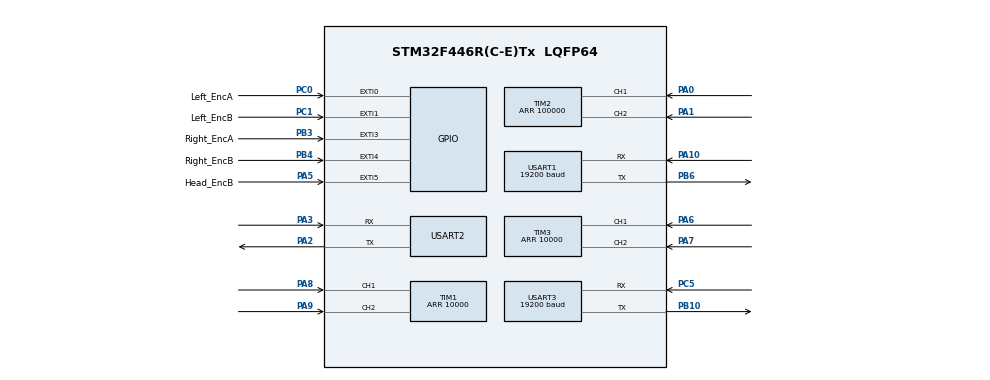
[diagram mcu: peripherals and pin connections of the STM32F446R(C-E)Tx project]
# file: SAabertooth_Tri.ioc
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Mcu.Family=STM32F4
Mcu.Name=STM32F446R(C-E)Tx
Mcu.Package=LQFP64
NVIC.EXTI0_IRQn=true\:0\:0\:false\:false\:true\:true\:true
NVIC.EXTI1_IRQn=true\:0\:0\:false\:false\:true\:true\:true
NVIC.EXTI3_IRQn=true\:0\:0\:false\:false\:true\:true\:true
NVIC.PriorityGroup=NVIC_PRIORITYGROUP_4
PA0-WKUP.Signal=S_TIM2_CH1_ETR
PA1.Signal=S_TIM2_CH2
PA10.Mode=Asynchronous
PA10.Signal=USART1_RX
PA13.Mode=Serial_Wire
PA13.Signal=SYS_JTMS-SWDIO
PA14.Mode=Serial_Wire
PA14.Signal=SYS_JTCK-SWCLK
PA2.Mode=Asynchronous
PA2.Signal=USART2_TX
PA3.Mode=Asynchronous
PA3.Signal=USART2_RX
PA5.GPIO_Label=Head_EncB
PA5.Signal=GPXTI5
PA6.Signal=S_TIM3_CH1
PA7.Signal=S_TIM3_CH2
PA8.Signal=S_TIM1_CH1
PA9.Signal=S_TIM1_CH2
PB10.Mode=Asynchronous
PB10.Signal=USART3_TX
PB3.GPIO_Label=Right_EncA
PB3.GPIO_PuPd=GPIO_PULLUP
PB3.Signal=GPXTI3
PB4.GPIO_Label=Right_EncB
PB4.Signal=GPXTI4
PB6.Mode=Asynchronous
PB6.Signal=USART1_TX
PC0.GPIO_Label=Left_EncA
PC0.Signal=GPXTI0
PC1.GPIO_Label=Left_EncB
PC1.GPIO_PuPd=GPIO_PULLUP
PC1.Signal=GPXTI1
PC5.Mode=Asynchronous
PC5.Signal=USART3_RX
PH0-OSC_IN.Mode=HSE-External-Oscillator
PH0-OSC_IN.Signal=RCC_OSC_IN
PH1-OSC_OUT.Mode=HSE-External-Oscillator
PH1-OSC_OUT.Signal=RCC_OSC_OUT
ProjectManager.HeapSize=0x200
ProjectManager.StackSize=0x400
ProjectManager.TargetToolchain=STM32CubeIDE
RCC.CortexFreq_Value=16000000
RCC.USBFreq_Value=96000000
RCC.VCOOutputFreq_Value=192000000
SH.S_TIM1_CH1.0=TIM1_CH1,Encoder_Interface
SH.S_TIM1_CH2.0=TIM1_CH2,Encoder_Interface
SH.S_TIM2_CH1_ETR.0=TIM2_CH1,Encoder_Interface
SH.S_TIM2_CH2.0=TIM2_CH2,Encoder_Interface
SH.S_TIM3_CH1.0=TIM3_CH1,Encoder_Interface
SH.S_TIM3_CH2.0=TIM3_CH2,Encoder_Interface
TIM1.Period=10000
TIM2.Period=100000
TIM3.Period=10000
USART1.BaudRate=19200
USART1.VirtualMode=VM_ASYNC
USART2.VirtualMode=VM_ASYNC
USART3.BaudRate=19200
USART3.VirtualMode=VM_ASYNC
board=custom

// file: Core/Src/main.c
/* USER CODE BEGIN Header */
/**
  ******************************************************************************
  * @file           : main.c
  * @brief          : Main program body
  ******************************************************************************
  * @attention
  *
  * <h2><center>&copy; Copyright (c) 2021 STMicroelectronics.
  * All rights reserved.</center></h2>
  *
  * This software component is licensed by ST under BSD 3-Clause license,
  * the "License"; You may not use this file except in compliance with the
  * License. You may obtain a copy of the License at:
  *                        opensource.org/licenses/BSD-3-Clause
  *
  ******************************************************************************
  */
/* USER CODE END Header */
#include "main.h"

/* USER CODE BEGIN PTD */
    void Write_Command(uint8_t , uint8_t);
	void motor(uint8_t motor , int8_t power);
	void SetBaudRate(uint16_t BaudRate);

	//Function Decleration For 2nd Sabertooth...

	void Write_CommandA(uint8_t, uint8_t);
	void motorA(uint8_t motor1 , int8_t power1);
	void SetBaudRateA(uint16_t BaudRate);
/* USER CODE END PTD */

TIM_HandleTypeDef htim1;
TIM_HandleTypeDef htim2;
TIM_HandleTypeDef htim3;

UART_HandleTypeDef huart1;
UART_HandleTypeDef huart2;
UART_HandleTypeDef huart3;

void SystemClock_Config(void);
static void MX_GPIO_Init(void);
static void MX_TIM1_Init(void);
static void MX_TIM2_Init(void);
static void MX_TIM3_Init(void);
static void MX_USART1_UART_Init(void);
static void MX_USART2_UART_Init(void);
static void MX_USART3_UART_Init(void);

int main(void)
{
  /* MCU Configuration--------------------------------------------------------*/
//Function Declaration for 1st Motor....

  /* Reset of all peripherals, Initializes the Flash interface and the Systick. */
  HAL_Init();

  /* Configure the system clock */
  SystemClock_Config();

  /* Initialize all configured peripherals */
  MX_GPIO_Init();
  MX_TIM1_Init();
  MX_TIM2_Init();
  MX_TIM3_Init();
  MX_USART1_UART_Init();
  MX_USART2_UART_Init();
  MX_USART3_UART_Init();
  /* USER CODE BEGIN 2 */
  SetBaudRate(19200);
  SetBaudRateA(19200);
  /* USER CODE END 2 */

  /* Infinite loop */
  while (1)
  {
	 motor(1,40);
	 motor(2,40);
	 motorA(2,40);
  }
}

//1st Sabertooth with 2 Motors i.e. Head Motor and Left Motor.....
void SetBaudRate(uint16_t BaudRate)
{
	  uint8_t value;
	  switch(BaudRate)
		{
			case 9600 : value = 2 ;
									break;
			case 19200: default : value = 3;
									break;
		}

		HAL_Delay(500);
		Write_Command(15 , value);
		HAL_Delay(2000);
}

char PacketAddress[2];
char Command[2];
char Value[2];
char AllWrite[2];
uint8_t packetaddress = 128;

void Write_Command(uint8_t command , uint8_t value)
{
	PacketAddress[0] = packetaddress;
	Command[0] = command;
	Value[0] = value;
	HAL_UART_Transmit(&huart1 , (uint8_t*)PacketAddress , 1 , 2000);
	HAL_UART_Transmit(&huart1 , (uint8_t*)Command , 1 ,2000);
	HAL_UART_Transmit(&huart1 , (uint8_t*)Value , 1 , 2000);
	AllWrite[0] = ((packetaddress + command + value) & 127);
	HAL_UART_Transmit(&huart1 , (uint8_t*)AllWrite , 1 , 2000);
}
void motor(uint8_t motor , int8_t power)
{
	Write_Command(((motor == 2?4:0) + (power<0?1:0)) , (power<0?-power:power));
}

//Second Sabertooth with Only 1 Motor....
void SetBaudRateA(uint16_t BaudRateA)
{
	  uint8_t valueA;
	  switch(BaudRateA)
		{
			case 9600 : valueA = 2 ;
									break;
			case 19200: default : valueA = 3;
									break;
		}

		HAL_Delay(500);
		Write_CommandA(15 , valueA);
		HAL_Delay(2000);
}

char PacketAddressA[2];
char CommandA[2];
char ValueA[2];
char AllWriteA[2];
uint8_t packetaddressA = 128;

void Write_CommandA(uint8_t commandA , uint8_t valueA)
{
	PacketAddressA[0] = packetaddressA;
	CommandA[0] = commandA;
	ValueA[0] = valueA;
	HAL_UART_Transmit(&huart3 , (uint8_t*)PacketAddressA , 1 , 2000);
	HAL_UART_Transmit(&huart3 , (uint8_t*)CommandA , 1 ,2000);
	HAL_UART_Transmit(&huart3 , (uint8_t*)ValueA , 1 , 2000);
	AllWriteA[0] = ((packetaddressA + commandA + valueA) & 127);
	HAL_UART_Transmit(&huart3 , (uint8_t*)AllWriteA , 1 , 2000);
}
void motorA(uint8_t motorA , int8_t powerA)
{
	Write_CommandA(((motorA == 2?4:0) + (powerA<0?1:0)) , (powerA<0?-powerA:powerA));
}

 // * @brief System Clock Configuration
  //* @retval None

void SystemClock_Config(void)
{
  RCC_OscInitTypeDef RCC_OscInitStruct = {0};
  RCC_ClkInitTypeDef RCC_ClkInitStruct = {0};

  /** Configure the main internal regulator output voltage
  */
  __HAL_RCC_PWR_CLK_ENABLE();
  __HAL_PWR_VOLTAGESCALING_CONFIG(PWR_REGULATOR_VOLTAGE_SCALE3);
  /** Initializes the RCC Oscillators according to the specified parameters
  * in the RCC_OscInitTypeDef structure.
  */
  RCC_OscInitStruct.OscillatorType = RCC_OSCILLATORTYPE_HSI;
  RCC_OscInitStruct.HSIState = RCC_HSI_ON;
  RCC_OscInitStruct.HSICalibrationValue = RCC_HSICALIBRATION_DEFAULT;
  RCC_OscInitStruct.PLL.PLLState = RCC_PLL_NONE;
  if (HAL_RCC_OscConfig(&RCC_OscInitStruct) != HAL_OK)
  {
    Error_Handler();
  }
  /** Initializes the CPU, AHB and APB buses clocks
  */
  RCC_ClkInitStruct.ClockType = RCC_CLOCKTYPE_HCLK|RCC_CLOCKTYPE_SYSCLK
                              |RCC_CLOCKTYPE_PCLK1|RCC_CLOCKTYPE_PCLK2;
  RCC_ClkInitStruct.SYSCLKSource = RCC_SYSCLKSOURCE_HSI;
  RCC_ClkInitStruct.AHBCLKDivider = RCC_SYSCLK_DIV1;
  RCC_ClkInitStruct.APB1CLKDivider = RCC_HCLK_DIV1;
  RCC_ClkInitStruct.APB2CLKDivider = RCC_HCLK_DIV1;

  if (HAL_RCC_ClockConfig(&RCC_ClkInitStruct, FLASH_LATENCY_0) != HAL_OK)
  {
    Error_Handler();
  }
}

/*
  * @brief TIM1 Initialization Function
  * @param None
  * @retval None
  */
static void MX_TIM1_Init(void)
{

  TIM_Encoder_InitTypeDef sConfig = {0};
  TIM_MasterConfigTypeDef sMasterConfig = {0};

  htim1.Instance = TIM1;
  htim1.Init.Prescaler = 0;
  htim1.Init.CounterMode = TIM_COUNTERMODE_UP;
  htim1.Init.Period = 10000;
  htim1.Init.ClockDivision = TIM_CLOCKDIVISION_DIV1;
  htim1.Init.RepetitionCounter = 0;
  htim1.Init.AutoReloadPreload = TIM_AUTORELOAD_PRELOAD_DISABLE;
  sConfig.EncoderMode = TIM_ENCODERMODE_TI1;
  sConfig.IC1Polarity = TIM_ICPOLARITY_RISING;
  sConfig.IC1Selection = TIM_ICSELECTION_DIRECTTI;
  sConfig.IC1Prescaler = TIM_ICPSC_DIV1;
  sConfig.IC1Filter = 0;
  sConfig.IC2Polarity = TIM_ICPOLARITY_RISING;
  sConfig.IC2Selection = TIM_ICSELECTION_DIRECTTI;
  sConfig.IC2Prescaler = TIM_ICPSC_DIV1;
  sConfig.IC2Filter = 0;
  if (HAL_TIM_Encoder_Init(&htim1, &sConfig) != HAL_OK)
  {
    Error_Handler();
  }
  sMasterConfig.MasterOutputTrigger = TIM_TRGO_RESET;
  sMasterConfig.MasterSlaveMode = TIM_MASTERSLAVEMODE_DISABLE;
  if (HAL_TIMEx_MasterConfigSynchronization(&htim1, &sMasterConfig) != HAL_OK)
  {
    Error_Handler();
  }

}

static void MX_TIM2_Init(void)
{

  TIM_Encoder_InitTypeDef sConfig = {0};
  TIM_MasterConfigTypeDef sMasterConfig = {0};

  htim2.Instance = TIM2;
  htim2.Init.Prescaler = 0;
  htim2.Init.CounterMode = TIM_COUNTERMODE_UP;
  htim2.Init.Period = 100000;
  htim2.Init.ClockDivision = TIM_CLOCKDIVISION_DIV1;
  htim2.Init.AutoReloadPreload = TIM_AUTORELOAD_PRELOAD_DISABLE;
  sConfig.EncoderMode = TIM_ENCODERMODE_TI1;
  sConfig.IC1Polarity = TIM_ICPOLARITY_RISING;
  sConfig.IC1Selection = TIM_ICSELECTION_DIRECTTI;
  sConfig.IC1Prescaler = TIM_ICPSC_DIV1;
  sConfig.IC1Filter = 0;
  sConfig.IC2Polarity = TIM_ICPOLARITY_RISING;
  sConfig.IC2Selection = TIM_ICSELECTION_DIRECTTI;
  sConfig.IC2Prescaler = TIM_ICPSC_DIV1;
  sConfig.IC2Filter = 0;
  if (HAL_TIM_Encoder_Init(&htim2, &sConfig) != HAL_OK)
  {
    Error_Handler();
  }
  sMasterConfig.MasterOutputTrigger = TIM_TRGO_RESET;
  sMasterConfig.MasterSlaveMode = TIM_MASTERSLAVEMODE_DISABLE;
  if (HAL_TIMEx_MasterConfigSynchronization(&htim2, &sMasterConfig) != HAL_OK)
  {
    Error_Handler();
  }

}

static void MX_TIM3_Init(void)
{

  TIM_Encoder_InitTypeDef sConfig = {0};
  TIM_MasterConfigTypeDef sMasterConfig = {0};

  htim3.Instance = TIM3;
  htim3.Init.Prescaler = 0;
  htim3.Init.CounterMode = TIM_COUNTERMODE_UP;
  htim3.Init.Period = 10000;
  htim3.Init.ClockDivision = TIM_CLOCKDIVISION_DIV1;
  htim3.Init.AutoReloadPreload = TIM_AUTORELOAD_PRELOAD_DISABLE;
  sConfig.EncoderMode = TIM_ENCODERMODE_TI1;
  sConfig.IC1Polarity = TIM_ICPOLARITY_RISING;
  sConfig.IC1Selection = TIM_ICSELECTION_DIRECTTI;
  sConfig.IC1Prescaler = TIM_ICPSC_DIV1;
  sConfig.IC1Filter = 0;
  sConfig.IC2Polarity = TIM_ICPOLARITY_RISING;
  sConfig.IC2Selection = TIM_ICSELECTION_DIRECTTI;
  sConfig.IC2Prescaler = TIM_ICPSC_DIV1;
  sConfig.IC2Filter = 0;
  if (HAL_TIM_Encoder_Init(&htim3, &sConfig) != HAL_OK)
  {
    Error_Handler();
  }
  sMasterConfig.MasterOutputTrigger = TIM_TRGO_RESET;
  sMasterConfig.MasterSlaveMode = TIM_MASTERSLAVEMODE_DISABLE;
  if (HAL_TIMEx_MasterConfigSynchronization(&htim3, &sMasterConfig) != HAL_OK)
  {
    Error_Handler();
  }

}

static void MX_USART1_UART_Init(void)
{

  huart1.Instance = USART1;
  huart1.Init.BaudRate = 19200;
  huart1.Init.WordLength = UART_WORDLENGTH_8B;
  huart1.Init.StopBits = UART_STOPBITS_1;
  huart1.Init.Parity = UART_PARITY_NONE;
  huart1.Init.Mode = UART_MODE_TX_RX;
  huart1.Init.HwFlowCtl = UART_HWCONTROL_NONE;
  huart1.Init.OverSampling = UART_OVERSAMPLING_16;
  if (HAL_UART_Init(&huart1) != HAL_OK)
  {
    Error_Handler();
  }

}

static void MX_USART2_UART_Init(void)
{

  huart2.Instance = USART2;
  huart2.Init.BaudRate = 115200;
  huart2.Init.WordLength = UART_WORDLENGTH_8B;
  huart2.Init.StopBits = UART_STOPBITS_1;
  huart2.Init.Parity = UART_PARITY_NONE;
  huart2.Init.Mode = UART_MODE_TX_RX;
  huart2.Init.HwFlowCtl = UART_HWCONTROL_NONE;
  huart2.Init.OverSampling = UART_OVERSAMPLING_16;
  if (HAL_UART_Init(&huart2) != HAL_OK)
  {
    Error_Handler();
  }

}

static void MX_USART3_UART_Init(void)
{

  huart3.Instance = USART3;
  huart3.Init.BaudRate = 19200;
  huart3.Init.WordLength = UART_WORDLENGTH_8B;
  huart3.Init.StopBits = UART_STOPBITS_1;
  huart3.Init.Parity = UART_PARITY_NONE;
  huart3.Init.Mode = UART_MODE_TX_RX;
  huart3.Init.HwFlowCtl = UART_HWCONTROL_NONE;
  huart3.Init.OverSampling = UART_OVERSAMPLING_16;
  if (HAL_UART_Init(&huart3) != HAL_OK)
  {
    Error_Handler();
  }

}

static void MX_GPIO_Init(void)
{
  GPIO_InitTypeDef GPIO_InitStruct = {0};

  /* GPIO Ports Clock Enable */
  __HAL_RCC_GPIOH_CLK_ENABLE();
  __HAL_RCC_GPIOC_CLK_ENABLE();
  __HAL_RCC_GPIOA_CLK_ENABLE();
  __HAL_RCC_GPIOB_CLK_ENABLE();

  /*Configure GPIO pin : Left_EncA_Pin */
  GPIO_InitStruct.Pin = Left_EncA_Pin;
  GPIO_InitStruct.Mode = GPIO_MODE_IT_RISING;
  GPIO_InitStruct.Pull = GPIO_NOPULL;
  HAL_GPIO_Init(Left_EncA_GPIO_Port, &GPIO_InitStruct);

  /*Configure GPIO pin : Left_EncB_Pin */
  GPIO_InitStruct.Pin = Left_EncB_Pin;
  GPIO_InitStruct.Mode = GPIO_MODE_IT_RISING;
  GPIO_InitStruct.Pull = GPIO_PULLUP;
  HAL_GPIO_Init(Left_EncB_GPIO_Port, &GPIO_InitStruct);

  /*Configure GPIO pin : Head_EncB_Pin */
  GPIO_InitStruct.Pin = Head_EncB_Pin;
  GPIO_InitStruct.Mode = GPIO_MODE_IT_RISING;
  GPIO_InitStruct.Pull = GPIO_NOPULL;
  HAL_GPIO_Init(Head_EncB_GPIO_Port, &GPIO_InitStruct);

  /*Configure GPIO pin : Right_EncA_Pin */
  GPIO_InitStruct.Pin = Right_EncA_Pin;
  GPIO_InitStruct.Mode = GPIO_MODE_IT_RISING;
  GPIO_InitStruct.Pull = GPIO_PULLUP;
  HAL_GPIO_Init(Right_EncA_GPIO_Port, &GPIO_InitStruct);

  /*Configure GPIO pin : Right_EncB_Pin */
  GPIO_InitStruct.Pin = Right_EncB_Pin;
  GPIO_InitStruct.Mode = GPIO_MODE_IT_RISING;
  GPIO_InitStruct.Pull = GPIO_NOPULL;
  HAL_GPIO_Init(Right_EncB_GPIO_Port, &GPIO_InitStruct);

  /* EXTI interrupt init*/
  HAL_NVIC_SetPriority(EXTI0_IRQn, 0, 0);
  HAL_NVIC_EnableIRQ(EXTI0_IRQn);

  HAL_NVIC_SetPriority(EXTI1_IRQn, 0, 0);
  HAL_NVIC_EnableIRQ(EXTI1_IRQn);

  HAL_NVIC_SetPriority(EXTI3_IRQn, 0, 0);
  HAL_NVIC_EnableIRQ(EXTI3_IRQn);

}

void Error_Handler(void)
{
  __disable_irq();
  while (1)
  {
  }
}

/************************ (C) COPYRIGHT STMicroelectronics *****END OF FILE****/
